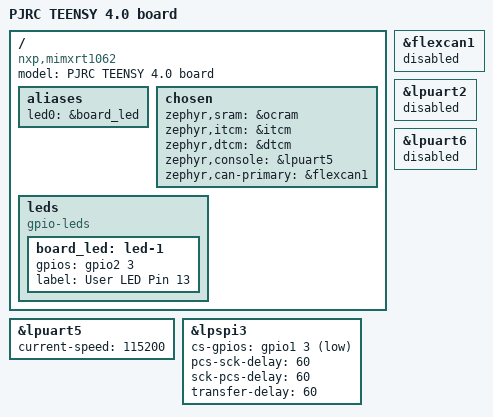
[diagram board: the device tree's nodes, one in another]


/ {
	model = "PJRC TEENSY 4.0 board";
	compatible = "nxp,mimxrt1062";

	aliases {
		led0 = &board_led;
	};

	chosen {
		zephyr,sram = &ocram;
		zephyr,itcm = &itcm;
		zephyr,dtcm = &dtcm;
		zephyr,console = &lpuart5; /* Teensy Pins 34(RX8) 35(TX8) */
		zephyr,can-primary = &flexcan1; /* Teensy Pins 23(CRX1) 22(CTX1) */
	};

	leds {
		compatible = "gpio-leds";
		board_led: led-1 {
			gpios = <&gpio2 3 GPIO_ACTIVE_HIGH>;
			label = "User LED Pin 13";
		};
	};
};

&lpuart5 {
	status = "okay";
	current-speed = < 115200 >;
};


teensy_spi1: &lpspi3 {
	status = "okay";
	cs-gpios = <&gpio1 3 GPIO_ACTIVE_LOW>; /* TeensyPin0 */
  pcs-sck-delay = < 60 >;
  sck-pcs-delay = < 60 >;
  transfer-delay = < 60 >;

	// wizenet@0 {
	// 	status = "okay";
	// 	compatible = "wiznet,w5500";
	// 	reg = <0>;
	// 	spi-max-frequency = <8000000>;
	// 	int-gpios = <&gpio2 19 GPIO_ACTIVE_LOW>;	/* */
	// 	reset-gpios = <&gpio2 18 GPIO_ACTIVE_LOW>;	/* */
	// 	label = "WIZ0";
	// };
};


&flexcan1 {
	status = "disabled";
};
&lpuart2 {
	status = "disabled";
};
&lpuart6 {
	status = "disabled";
};
